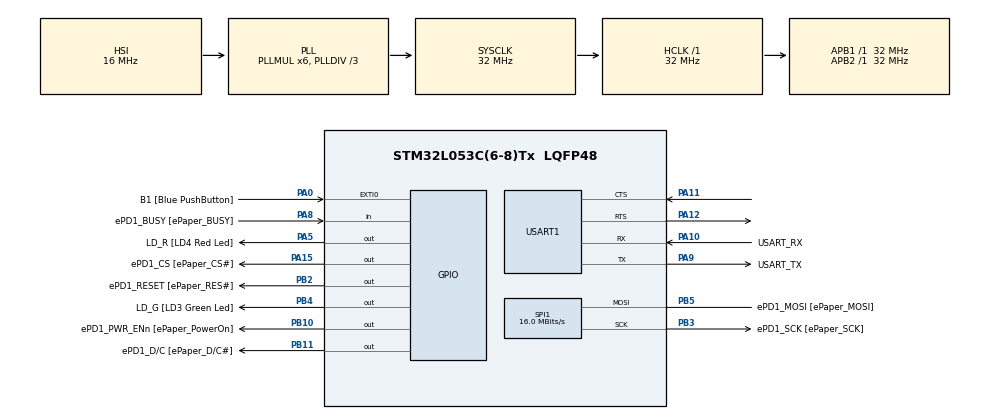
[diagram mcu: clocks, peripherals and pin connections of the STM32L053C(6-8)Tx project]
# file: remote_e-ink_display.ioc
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Mcu.Family=STM32L0
PH0-OSC_IN.Signal=RCC_OSC_IN
PB10.GPIO_Speed=GPIO_SPEED_FREQ_LOW
SPI1.VirtualType=VM_MASTER
PB10.GPIO_PuPd=GPIO_NOPULL
PA8.GPIO_Mode=GPIO_MODE_INPUT
PA14.GPIO_Label=SWCLK
PB2.GPIO_Speed=GPIO_SPEED_FREQ_LOW
PA0.GPIO_Label=B1 [Blue PushButton]
PA11.Mode=CTS_RTS
PB11.GPIO_PuPd=GPIO_NOPULL
PB11.Signal=GPIO_Output
PB3.GPIO_Speed=GPIO_SPEED_FREQ_LOW
RCC.SYSCLKSource=RCC_SYSCLKSOURCE_PLLCLK
ProjectManager.StackSize=0x400
PB11.GPIO_Speed=GPIO_SPEED_FREQ_LOW
RCC.HSI48MClockSelection=RCC_USBCLKSOURCE_HSI48
PA15.GPIO_Label=ePD1_CS [ePaper_CS\#]
PB10.GPIO_ModeDefaultOutputPP=GPIO_MODE_OUTPUT_PP
PA12.Signal=USART1_RTS
RCC.PLLDIV=RCC_PLLDIV_3
SPI1.Direction=SPI_DIRECTION_1LINE
RCC.HCLKFreq_Value=32000000
RCC.APB2TimFreq_Value=32000000
SPI1.CalculateBaudRate=16.0 MBits/s
RCC.AHBFreq_Value=32000000
PH0-OSC_IN.Mode=HSE-External-Clock-Source
PH0-OSC_IN.GPIO_Label=MCO
RCC.HSE_VALUE=8000000
PB2.Signal=GPIO_Output
PB3.Mode=Simplex_Bidirectional_Master
RCC.PLLMUL=RCC_PLLMUL_6
PB3.GPIO_PuPd=GPIO_NOPULL
RCC.RTCClockSelectionVirtual=RCC_RTCCLKSOURCE_LSE
PA14.Mode=Serial_Wire
PA5.GPIO_PuPd=GPIO_NOPULL
PB5.Mode=Simplex_Bidirectional_Master
PA10.GPIO_Label=USART_RX
PA8.Signal=GPIO_Input
PB2.GPIO_PuPd=GPIO_NOPULL
PA0.Signal=GPXTI0
Mcu.Package=LQFP48
PA10.Signal=USART1_RX
PA15.Signal=GPIO_Output
PB5.GPIO_Speed=GPIO_SPEED_FREQ_LOW
PB5.GPIO_Label=ePD1_MOSI [ePaper_MOSI]
RCC.APB1TimFreq_Value=32000000
NVIC.USART1_IRQn=true\:0\:0\:false\:false\:true\:true\:true
SPI1.BaudRatePrescaler=SPI_BAUDRATEPRESCALER_2
PB2.GPIO_ModeDefaultOutputPP=GPIO_MODE_OUTPUT_PP
RCC.HSI48_VALUE=48000000
PB4.Signal=GPIO_Output
PB4.GPIO_ModeDefaultOutputPP=GPIO_MODE_OUTPUT_PP
PB3.GPIO_Label=ePD1_SCK [ePaper_SCK]
PB5.GPIO_Mode=GPIO_MODE_AF_PP
RCC.MSI_VALUE=2097000
PA10.Mode=Asynchronous
PA9.GPIO_Label=USART_TX
PB11.GPIO_Label=ePD1_D/C [ePaper_D/C\#]
USART1.VirtualMode-Asynchronous=VM_ASYNC
PA13.Signal=SYS_SWDIO
RCC.HSI16_VALUE=16000000
PA9.Mode=Asynchronous
PA8.GPIO_Label=ePD1_BUSY [ePaper_BUSY]
ProjectManager.TargetToolchain=Makefile
PB10.GPIO_Label=ePD1_PWR_ENn [ePaper_PowerOn]
PA9.Signal=USART1_TX
PB4.GPIO_PuPd=GPIO_NOPULL
RCC.LSE_VALUE=32768
PB11.GPIO_ModeDefaultOutputPP=GPIO_MODE_OUTPUT_PP
PB10.Signal=GPIO_Output
PA5.Signal=GPIO_Output
board=STM32L0538-DISCO
RCC.VCOOutputFreq_Value=96000000
PB4.GPIO_Speed=GPIO_SPEED_FREQ_LOW
RCC.APB2Freq_Value=32000000
PB4.GPIO_Label=LD_G [LD3 Green Led]
PA5.GPIO_ModeDefaultOutputPP=GPIO_MODE_OUTPUT_PP
SPI1.Mode=SPI_MODE_MASTER
PB3.GPIO_Mode=GPIO_MODE_AF_PP
PA13.Mode=Serial_Wire
Mcu.Name=STM32L053C(6-8)Tx
PA13.GPIO_Label=SWDIO
PB3.Signal=SPI1_SCK
RCC.SYSCLKFreq_VALUE=32000000
PB5.Signal=SPI1_MOSI
PA12.Mode=CTS_RTS
PA5.GPIO_Label=LD_R [LD4 Red Led]
PB5.GPIO_PuPd=GPIO_NOPULL
PA11.Signal=USART1_CTS
PA14.Signal=SYS_SWCLK
PB2.GPIO_Label=ePD1_RESET [ePaper_RES\#]
ProjectManager.HeapSize=0x200
RCC.HSI_VALUE=16000000
PA8.GPIO_PuPd=GPIO_NOPULL
PA5.GPIO_Speed=GPIO_SPEED_FREQ_LOW
RCC.APB1Freq_Value=32000000
VP_CRC_VS_CRC.Mode=CRC_Activate
NVIC.EXTI0_1_IRQn=true\:0\:0\:false\:false\:true\:true\:true

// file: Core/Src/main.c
/* USER CODE BEGIN Header */
/**
  ******************************************************************************
  * @file           : main.c
  * @brief          : Main program body
  ******************************************************************************
  * @attention
  *
  * <h2><center>&copy; Copyright (c) 2020 STMicroelectronics.
  * All rights reserved.</center></h2>
  *
  * This software component is licensed by ST under BSD 3-Clause license,
  * the "License"; You may not use this file except in compliance with the
  * License. You may obtain a copy of the License at:
  *                        opensource.org/licenses/BSD-3-Clause
  *
  ******************************************************************************
  */
/* USER CODE END Header */

#include "main.h"
#include "crc.h"
#include "spi.h"
#include "usart.h"
#include "gpio.h"

/* USER CODE BEGIN Includes */
#include "app.h"
/* USER CODE END Includes */

void SystemClock_Config(void);

int main(void)
{

  /* MCU Configuration--------------------------------------------------------*/

  /* Reset of all peripherals, Initializes the Flash interface and the Systick. */
  HAL_Init();

  /* Configure the system clock */
  SystemClock_Config();

  /* Initialize all configured peripherals */
  MX_GPIO_Init();
  MX_SPI1_Init();
  MX_USART1_UART_Init();
  MX_CRC_Init();

  /* Infinite loop */
  /* USER CODE BEGIN WHILE */
  app_init();
  while (1)
  {
      app_periodic();
    /* USER CODE END WHILE */

  }
}

void SystemClock_Config(void)
{
  RCC_OscInitTypeDef RCC_OscInitStruct = {0};
  RCC_ClkInitTypeDef RCC_ClkInitStruct = {0};
  RCC_PeriphCLKInitTypeDef PeriphClkInit = {0};

  /** Configure the main internal regulator output voltage
  */
  __HAL_PWR_VOLTAGESCALING_CONFIG(PWR_REGULATOR_VOLTAGE_SCALE1);
  /** Initializes the CPU, AHB and APB busses clocks
  */
  RCC_OscInitStruct.OscillatorType = RCC_OSCILLATORTYPE_HSI;
  RCC_OscInitStruct.HSIState = RCC_HSI_ON;
  RCC_OscInitStruct.HSICalibrationValue = RCC_HSICALIBRATION_DEFAULT;
  RCC_OscInitStruct.PLL.PLLState = RCC_PLL_ON;
  RCC_OscInitStruct.PLL.PLLSource = RCC_PLLSOURCE_HSI;
  RCC_OscInitStruct.PLL.PLLMUL = RCC_PLLMUL_6;
  RCC_OscInitStruct.PLL.PLLDIV = RCC_PLLDIV_3;
  if (HAL_RCC_OscConfig(&RCC_OscInitStruct) != HAL_OK)
  {
    Error_Handler();
  }
  /** Initializes the CPU, AHB and APB busses clocks
  */
  RCC_ClkInitStruct.ClockType = RCC_CLOCKTYPE_HCLK|RCC_CLOCKTYPE_SYSCLK
                              |RCC_CLOCKTYPE_PCLK1|RCC_CLOCKTYPE_PCLK2;
  RCC_ClkInitStruct.SYSCLKSource = RCC_SYSCLKSOURCE_PLLCLK;
  RCC_ClkInitStruct.AHBCLKDivider = RCC_SYSCLK_DIV1;
  RCC_ClkInitStruct.APB1CLKDivider = RCC_HCLK_DIV1;
  RCC_ClkInitStruct.APB2CLKDivider = RCC_HCLK_DIV1;

  if (HAL_RCC_ClockConfig(&RCC_ClkInitStruct, FLASH_LATENCY_1) != HAL_OK)
  {
    Error_Handler();
  }
  PeriphClkInit.PeriphClockSelection = RCC_PERIPHCLK_USART1;
  PeriphClkInit.Usart1ClockSelection = RCC_USART1CLKSOURCE_PCLK2;
  if (HAL_RCCEx_PeriphCLKConfig(&PeriphClkInit) != HAL_OK)
  {
    Error_Handler();
  }
}

void Error_Handler(void)
{
}

/************************ (C) COPYRIGHT STMicroelectronics *****END OF FILE****/
